VERSION "WFR ASB service brake v0.1 (recruit project, IDs are placeholders - align with the WFR CAN map)"

NS_ :

BS_:

BU_: AS_COMPUTER ASB_SBC

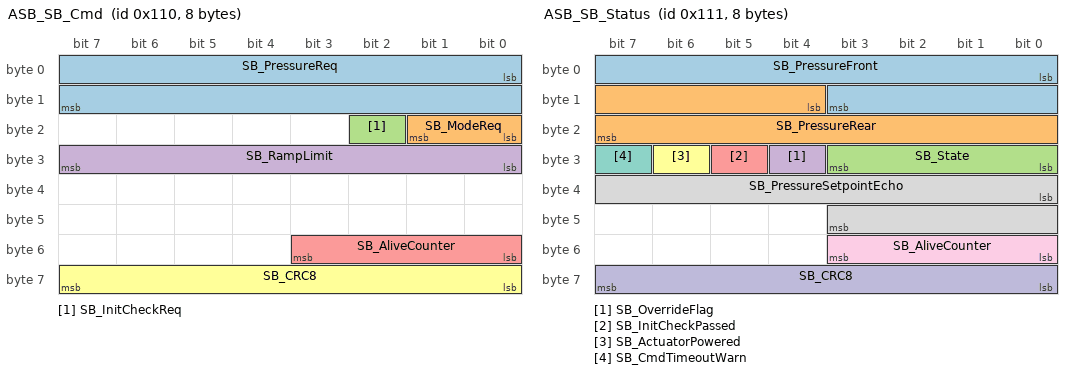
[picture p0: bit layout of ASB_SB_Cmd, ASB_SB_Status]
BO_ 272 ASB_SB_Cmd: 8 AS_COMPUTER
 SG_ SB_PressureReq : 0|16@1+ (0.01,0) [0|200] "bar" ASB_SBC
 SG_ SB_ModeReq : 16|2@1+ (1,0) [0|3] "" ASB_SBC
 SG_ SB_InitCheckReq : 18|1@1+ (1,0) [0|1] "" ASB_SBC
 SG_ SB_RampLimit : 24|8@1+ (10,0) [0|2550] "bar/s" ASB_SBC
 SG_ SB_AliveCounter : 48|4@1+ (1,0) [0|15] "" ASB_SBC
 SG_ SB_CRC8 : 56|8@1+ (1,0) [0|255] "" ASB_SBC

BO_ 273 ASB_SB_Status: 8 ASB_SBC
 SG_ SB_PressureFront : 0|12@1+ (0.05,0) [0|204.75] "bar" AS_COMPUTER
 SG_ SB_PressureRear : 12|12@1+ (0.05,0) [0|204.75] "bar" AS_COMPUTER
 SG_ SB_State : 24|4@1+ (1,0) [0|15] "" AS_COMPUTER
 SG_ SB_OverrideFlag : 28|1@1+ (1,0) [0|1] "" AS_COMPUTER
 SG_ SB_InitCheckPassed : 29|1@1+ (1,0) [0|1] "" AS_COMPUTER
 SG_ SB_ActuatorPowered : 30|1@1+ (1,0) [0|1] "" AS_COMPUTER
 SG_ SB_CmdTimeoutWarn : 31|1@1+ (1,0) [0|1] "" AS_COMPUTER
 SG_ SB_PressureSetpointEcho : 32|12@1+ (0.05,0) [0|204.75] "bar" AS_COMPUTER
 SG_ SB_AliveCounter : 48|4@1+ (1,0) [0|15] "" AS_COMPUTER
 SG_ SB_CRC8 : 56|8@1+ (1,0) [0|255] "" AS_COMPUTER

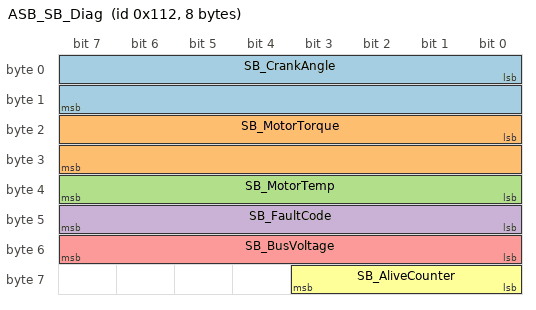
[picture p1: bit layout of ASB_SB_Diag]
BO_ 274 ASB_SB_Diag: 8 ASB_SBC
 SG_ SB_CrankAngle : 0|16@1- (0.01,0) [-327.68|327.67] "deg" AS_COMPUTER
 SG_ SB_MotorTorque : 16|16@1- (0.01,0) [-327.68|327.67] "Nm" AS_COMPUTER
 SG_ SB_MotorTemp : 32|8@1+ (1,-40) [-40|215] "degC" AS_COMPUTER
 SG_ SB_FaultCode : 40|8@1+ (1,0) [0|255] "" AS_COMPUTER
 SG_ SB_BusVoltage : 48|8@1+ (0.25,0) [0|63.75] "V" AS_COMPUTER
 SG_ SB_AliveCounter : 56|4@1+ (1,0) [0|15] "" AS_COMPUTER

CM_ BU_ AS_COMPUTER "Autonomous-system computer (controller node via the vehicle CAN gateway).";
CM_ BU_ ASB_SBC "Service-brake controller: reads 2x brake-pressure sensors, drives the CAN servo on a private bus.";
CM_ BO_ 272 "Service-brake command, 100 Hz. Frames with a bad CRC8 or a repeated alive counter count as missing.";
CM_ BO_ 273 "Service-brake status, 100 Hz. Also the SBC heartbeat for the AS supervisor (lost after 50 ms).";
CM_ BO_ 274 "Service-brake diagnostics, 20 Hz.";
CM_ SG_ 272 SB_PressureReq "Front-circuit line pressure setpoint.";
CM_ SG_ 272 SB_ModeReq "0 PARK (back off fully), 1 READY (crank 0.5 mm short of contact), 2 ACTIVE (pressure control).";
CM_ SG_ 272 SB_RampLimit "Max setpoint slew; 0 selects the default 600 bar/s.";
CM_ SG_ 272 SB_CRC8 "SAE J1850 CRC-8 (poly 0x1D, init 0xFF, xor-out 0xFF) over bytes 0-6.";
CM_ SG_ 273 SB_OverrideFlag "Latched when the driver brakes harder than commanded; cleared by a zero command.";
CM_ SG_ 273 SB_ActuatorPowered "Read back from the hardware power interlock (actuator supply only with ASMS on).";
CM_ SG_ 273 SB_CmdTimeoutWarn "Set after 50 ms without a valid command; SAFE_STOP after 100 ms.";

BA_DEF_ BO_ "GenMsgCycleTime" INT 0 10000;
BA_DEF_DEF_ "GenMsgCycleTime" 0;
BA_ "GenMsgCycleTime" BO_ 272 10;
BA_ "GenMsgCycleTime" BO_ 273 10;
BA_ "GenMsgCycleTime" BO_ 274 50;

VAL_ 272 SB_ModeReq 0 "PARK" 1 "READY" 2 "ACTIVE" 3 "RESERVED" ;
VAL_ 273 SB_State 0 "OFF" 1 "PARKED" 2 "READY" 3 "ACTIVE" 4 "OVERRIDE" 5 "SAFE_STOP" 6 "INIT_CHECK" 7 "FAULT" ;
VAL_ 274 SB_FaultCode 0 "NONE" 1 "CMD_LOST" 2 "SENSOR_FRONT_RANGE" 3 "SENSOR_REAR_RANGE" 4 "PRESSURE_IMPLAUSIBLE" 5 "MOTOR_FAULT" 6 "ENCODER_FAULT" 7 "OVER_TEMP" 8 "INIT_CHECK_FAILED" 9 "HARD_STOP_HIT" ;
